AUTOSAR XML (schema 00049)
package /Components
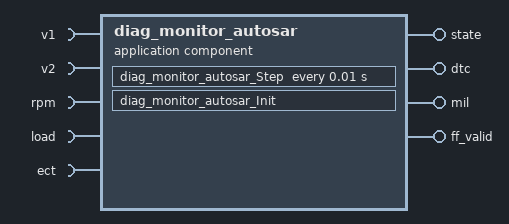
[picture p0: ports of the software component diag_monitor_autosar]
  application sw component type diag_monitor_autosar
    5 x require port:
      v1: nonqueued-receiver-com-spec{data-element=v1, init-value=0}, required-interface=v1
      v2: nonqueued-receiver-com-spec{data-element=v2, init-value=0}, required-interface=v2
      rpm: nonqueued-receiver-com-spec{data-element=rpm, init-value=0}, required-interface=rpm
      load: nonqueued-receiver-com-spec{data-element=load, init-value=0}, required-interface=load
      ect: nonqueued-receiver-com-spec{data-element=ect, init-value=0}, required-interface=ect
    4 x provide port:
      state: nonqueued-sender-com-spec{data-element=state, init-value=0}, provided-interface=state
      dtc: nonqueued-sender-com-spec{data-element=dtc, init-value=0}, provided-interface=dtc
      mil: nonqueued-sender-com-spec{data-element=mil, init-value=0}, provided-interface=mil
      ff_valid: nonqueued-sender-com-spec{data-element=ff_valid, init-value=0}, provided-interface=ff_valid
    behavior diag_monitor_autosar_IB: handle-termination-and-restart=NO-SUPPORT
      timing event Event_diag_monitor_autosar_Step: start-on-event=diag_monitor_autosar_Step, period=0.01
      runnable diag_monitor_autosar_Init
      runnable diag_monitor_autosar_Step
        data-read-access:
          access IN_ect_ect: accessed-variable=ect.ect
          access IN_v1_v1: accessed-variable=v1.v1
          access IN_v2_v2: accessed-variable=v2.v2
        data-write-access:
          4 x access:
            OUT_state_state: accessed-variable=state.state
            OUT_dtc_dtc: accessed-variable=dtc.dtc
            OUT_mil_mil: accessed-variable=mil.mil
            OUT_ff_valid_ff_valid: accessed-variable=ff_valid.ff_valid
